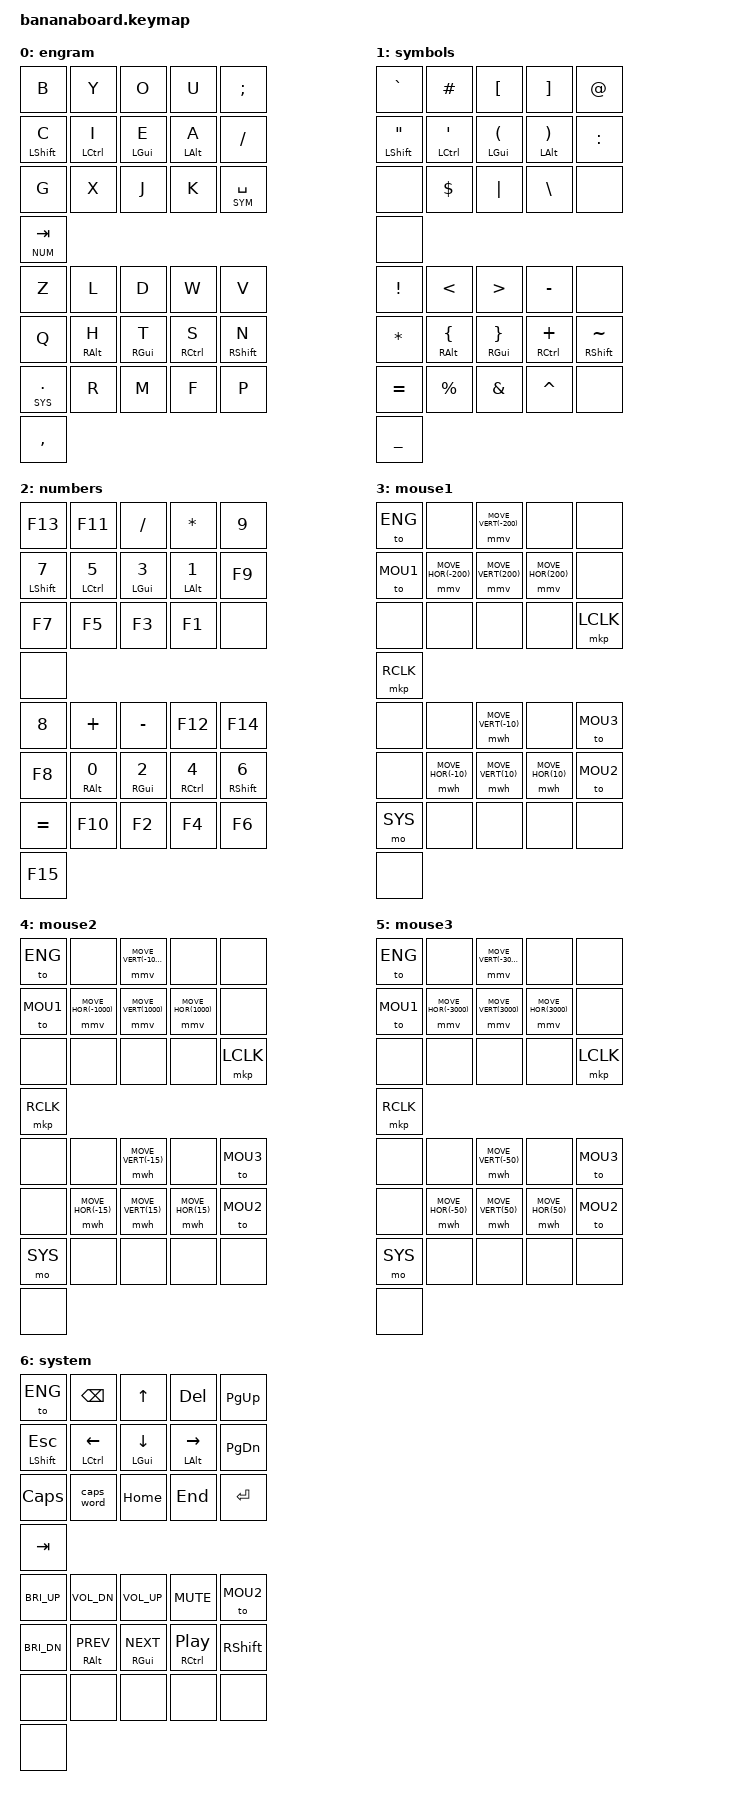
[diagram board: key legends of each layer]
#include <behaviors.dtsi>
#include <dt-bindings/zmk/keys.h>
#include <dt-bindings/zmk/bt.h>
#include <dt-bindings/zmk/mouse.h>

#define ENG 0
#define SYM 1
#define NUM 2
#define MOU1 3
#define MOU2 4
#define MOU3 5
#define SYS 6

&mmv {
    acceleration-exponent = <0>;
};
&mwh {
    acceleration-exponent = <0>;
};

/ {

    // 0  1  2  3  4
    // 5  6  7  8  9
    // 10 11 12 13 14
    //          15
    // 16 17 18 19 20
    // 21 22 23 24 25
    // 26 27 28 29 30
    //    31

    combos {
        compatible = "zmk,combos";
        combo_btclr {
            timeout-ms = <50>;
            key-positions = <5 6 7 8>;
            bindings = <&bt BT_CLR>;
        };
        combo_btsel0 {
            timeout-ms = <50>;
            key-positions = <6 7 8>;
            bindings = <&bt BT_SEL 0>;
        };
        combo_btsel1 {
            timeout-ms = <50>;
            key-positions = <5 6 7>;
            bindings = <&bt BT_SEL 1>;
        };
        combo_btsel2 {
            timeout-ms = <50>;
            key-positions = <5 6 8>;
            bindings = <&bt BT_SEL 2>;
        };
        combo_btsel3 {
            timeout-ms = <50>;
            key-positions = <5 7 8>;
            bindings = <&bt BT_SEL 3>;
        };
    };

    behaviors {
        bhm: balanced_homerow_mods {
            compatible = "zmk,behavior-hold-tap";
            label = "HOMEROW_MODS";
            #binding-cells = <2>;
            tapping-term-ms = <200>;
            quick-tap-ms = <200>;
            flavor = "balanced";
            bindings = <&kp>, <&kp>;
        };

        blt: balanced_layer_tap {
            compatible = "zmk,behavior-hold-tap";
            label = "LAYER_TAPS";
            #binding-cells = <2>;
            tapping-term-ms = <200>;
            quick-tap-ms = <200>;
            flavor = "balanced";
            bindings = <&mo>, <&kp>;
        };
    };

    keymap {
        compatible = "zmk,keymap";

        engram {
            bindings = <
            &kp B  &kp Y  &kp O  &kp U  &kp SEMI
            &bhm LSHIFT C  &bhm LCTRL I  &bhm LGUI E  &bhm LALT A  &kp FSLH
            &kp G  &kp X  &kp J  &kp K  &blt SYM SPC
            &blt NUM TAB
            &kp Z  &kp L  &kp D  &kp W  &kp V
            &kp Q  &bhm RALT H  &bhm RGUI T  &bhm RCTRL S  &bhm RSHIFT N
            &blt SYS DOT  &kp R  &kp M  &kp F  &kp P
            &kp COMMA
            >;
        };

        symbols {
            bindings = <
            &kp GRAVE  &kp HASH  &kp LBKT  &kp RBKT  &kp AT
            &bhm LSHIFT DQT  &bhm LCTRL SQT  &bhm LGUI LPAR  &bhm LALT RPAR  &kp COLON
            &none  &kp DLLR  &kp PIPE  &kp BSLH  &none
            &none
            &kp EXCL  &kp LT  &kp GT  &kp MINUS  &none
            &kp STAR  &bhm RALT LBRC  &bhm RGUI RBRC  &bhm RCTRL PLUS  &bhm RSHIFT TILDE
            &kp EQUAL  &kp PRCNT  &kp AMPS  &kp CARET  &none
            &kp UNDER
            >;
        };

        numbers {
            bindings = <
            &kp F13  &kp F11  &kp FSLH  &kp STAR  &kp N9
            &bhm LSHIFT N7  &bhm LCTRL N5  &bhm LGUI N3  &bhm LALT N1  &kp F9
            &kp F7  &kp F5  &kp F3  &kp F1  &none
            &none
            &kp N8  &kp PLUS  &kp MINUS  &kp F12  &kp F14
            &kp F8  &bhm RALT N0  &bhm RGUI N2  &bhm RCTRL N4  &bhm RSHIFT N6
            &kp EQUAL  &kp F10  &kp F2  &kp F4 &kp F6
            &kp F15
            >;
        };

        mouse1 {
            bindings = <
            &to ENG  &none  &mmv MOVE_VERT(-200)  &none  &none
            &to MOU1  &mmv MOVE_HOR(-200)  &mmv MOVE_VERT(200)  &mmv MOVE_HOR(200)  &none
            &none  &none  &none  &none  &mkp LCLK
            &mkp RCLK
            &none  &none  &mwh MOVE_VERT(-10)  &none  &to MOU3
            &none  &mwh MOVE_HOR(-10)  &mwh MOVE_VERT(10)  &mwh MOVE_HOR(10)  &to MOU2
            &mo SYS  &none  &none  &none  &none
            &none
            >;
        };

        mouse2 {
            bindings = <
            &to ENG  &none  &mmv MOVE_VERT(-1000)  &none  &none
            &to MOU1  &mmv MOVE_HOR(-1000)  &mmv MOVE_VERT(1000)  &mmv MOVE_HOR(1000)  &none
            &none  &none  &none  &none  &mkp LCLK
            &mkp RCLK
            &none  &none  &mwh MOVE_VERT(-15)  &none  &to MOU3
            &none  &mwh MOVE_HOR(-15)  &mwh MOVE_VERT(15)  &mwh MOVE_HOR(15)  &to MOU2
            &mo SYS  &none  &none  &none  &none
            &none
            >;
        };

        mouse3 {
            bindings = <
            &to ENG  &none  &mmv MOVE_VERT(-3000)  &none  &none
            &to MOU1  &mmv MOVE_HOR(-3000)  &mmv MOVE_VERT(3000)  &mmv MOVE_HOR(3000)  &none
            &none  &none  &none  &none  &mkp LCLK
            &mkp RCLK
            &none  &none  &mwh MOVE_VERT(-50)  &none  &to MOU3
            &none  &mwh MOVE_HOR(-50)  &mwh MOVE_VERT(50)  &mwh MOVE_HOR(50)  &to MOU2
            &mo SYS  &none  &none  &none  &none
            &none
            >;
        };

        system {
            bindings = <
            &to ENG  &kp BSPC  &kp UP  &kp DEL  &kp PG_UP
            &bhm LSHIFT ESC  &bhm LCTRL LEFT  &bhm LGUI DOWN  &bhm LALT RIGHT  &kp PG_DN
            &kp CAPS  &caps_word  &kp HOME  &kp END  &kp RET
            &kp TAB
            &kp C_BRI_UP  &kp C_VOL_DN  &kp C_VOL_UP  &kp C_MUTE  &to MOU2
            &kp C_BRI_DN  &bhm RALT C_PREV  &bhm RGUI C_NEXT  &bhm RCTRL C_PP  &kp RSHIFT
            &none  &none  &none  &none  &none
            &none
            >;
        };

    };
};
